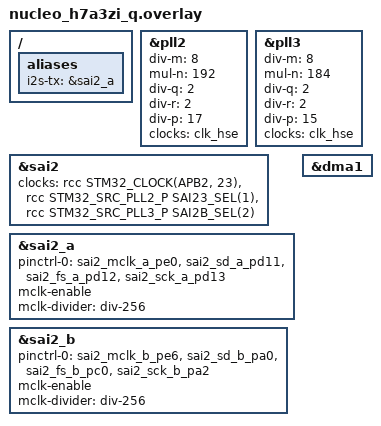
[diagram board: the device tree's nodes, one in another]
/*
 * Copyright (c) 2026 Mario Paja
 *
 * SPDX-License-Identifier: Apache-2.0
 */

/ {
	aliases {
		i2s-tx = &sai2_a;
	};
};

&pll2 {
	/* 44.1KHz (0.03% Error) - PLL2_P SEL(1)  */
	div-m = <8>;
	mul-n = <192>;
	div-q = <2>;
	div-r = <2>;
	div-p = <17>;
	clocks = <&clk_hse>;
	status = "okay";
};


&pll3 {
	/* 48KHz (0.17% Error) - PLL3_P SEL(2) */
	div-m = <8>;
	mul-n = <184>;
	div-q = <2>;
	div-r = <2>;
	div-p = <15>;
	clocks = <&clk_hse>;
	status = "okay";
};

&sai2 {
	status = "okay";
	clocks = <&rcc STM32_CLOCK(APB2, 23)>,
			 <&rcc STM32_SRC_PLL2_P SAI23_SEL(1)>,
			 <&rcc STM32_SRC_PLL3_P SAI2B_SEL(2)>;
	clock-names = "sai_ck", "sai_a_ker_ck", "sai_b_ker_ck";
};

&sai2_a {
	pinctrl-0 = <&sai2_mclk_a_pe0 &sai2_sd_a_pd11
		     &sai2_fs_a_pd12 &sai2_sck_a_pd13>;
	pinctrl-names = "default";
	status = "okay";
	mclk-enable;
	mclk-divider = "div-256";
	dma-names = "tx";
};

&sai2_b {
	pinctrl-0 = <&sai2_mclk_b_pe6 &sai2_sd_b_pa0
		     &sai2_fs_b_pc0 &sai2_sck_b_pa2>;
	pinctrl-names = "default";
	status = "okay";
	mclk-enable;
	mclk-divider = "div-256";
	dma-names = "tx";
};

&dma1 {
	status = "okay";
};
